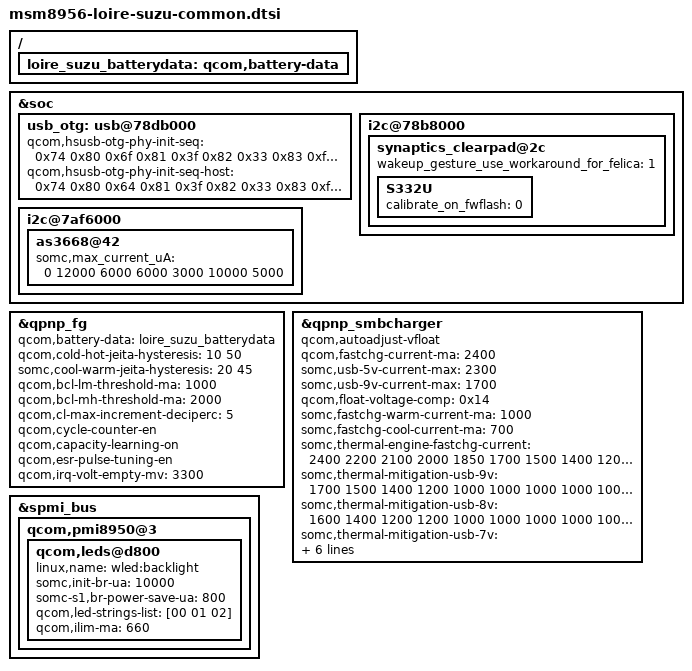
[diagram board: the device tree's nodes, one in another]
/* arch/arm64/boot/dts/qcom/msm8956-loire-suzu-common.dtsi
 *
 * This program is free software; you can redistribute it and/or modify
 * it under the terms of the GNU General Public License version 2 and
 * only version 2 as published by the Free Software Foundation.
 *
 * This program is distributed in the hope that it will be useful,
 * but WITHOUT ANY WARRANTY; without even the implied warranty of
 * MERCHANTABILITY or FITNESS FOR A PARTICULAR PURPOSE.  See the
 * GNU General Public License for more details.
 */
/*
 * Copyright (C) 2015 Sony Mobile Communications Inc.
 *
 * This program is free software; you can redistribute it and/or modify
 * it under the terms of the GNU General Public License version 2, as
 * published by the Free Software Foundation.
 */

&soc {
	usb_otg: usb@78db000 {
		qcom,hsusb-otg-phy-init-seq =
			<0x74 0x80 0x6f 0x81 0x3f 0x82 0x33 0x83 0xffffffff>;
		qcom,hsusb-otg-phy-init-seq-host =
			<0x74 0x80 0x64 0x81 0x3f 0x82 0x33 0x83 0xffffffff>;
	};

	/* I2C : BLSP4 */
	i2c@78b8000 { /* BLSP1 QUP3 */
		synaptics_clearpad@2c {
			wakeup_gesture_use_workaround_for_felica = <1>;
			/* chip settings */
			S332U {
				calibrate_on_fwflash = <0>;
			};
		};
	};
	/* I2C : BLSP6 */
	i2c@7af6000 { /* BLSP2 QUP1 */
		as3668@42 {
			somc,max_current_uA = <0 12000 6000 6000 3000 10000 5000>;
		};
	};
};

/{
	loire_suzu_batterydata: qcom,battery-data {
		#include "batterydata-loire-suzu-send.dtsi"
		#include "batterydata-loire-suzu-atl.dtsi"
	};
};

&qpnp_fg {
	qcom,battery-data = <&loire_suzu_batterydata>;
	qcom,cold-hot-jeita-hysteresis = <10 50>;
	somc,cool-warm-jeita-hysteresis = <20 45>;
	qcom,bcl-lm-threshold-ma = <1000>;
	qcom,bcl-mh-threshold-ma = <2000>;
	qcom,cl-max-increment-deciperc = <5>;
	qcom,cycle-counter-en;
	qcom,capacity-learning-on;
	qcom,esr-pulse-tuning-en;
	qcom,irq-volt-empty-mv = <3300>;
};

&qpnp_smbcharger {
	qcom,autoadjust-vfloat;
	qcom,fastchg-current-ma = <2400>;
	somc,usb-5v-current-max = <2300>;
	somc,usb-9v-current-max = <1700>;
	qcom,float-voltage-comp = <0x14>;
	somc,fastchg-warm-current-ma = <1000>;
	somc,fastchg-cool-current-ma = <700>;
	somc,thermal-engine-fastchg-current = <2400 2200 2100 2000 1850 1700 1500 1400 1200 1100 1100 1000 1000 700 450>;
	somc,thermal-mitigation-usb-9v = <1700 1500 1400 1200 1000 1000 1000 1000 1000 900 700 500 450 300 300>;
	somc,thermal-mitigation-usb-8v = <1600 1400 1200 1200 1000 1000 1000 1000 1000 900 700 500 450 300 300>;
	somc,thermal-mitigation-usb-7v = <1500 1500 1400 1200 1000 1000 1000 1000 1000 900 700 500 450 300 300>;
	somc,thermal-mitigation-usb-6v = <1400 1400 1200 1200 1200 1000 1000 1000 1000 900 700 500 450 300 300>;
	somc,thermal-mitigation-usb-5v = <2300 2200 2100 2000 1800 1600 1400 1200 1200 1100 900 700 500 450 300>;
	somc,limit-usb-5v-level = <15>;
};

&spmi_bus {
	qcom,pmi8950@3 {
		qcom,leds@d800 {
			linux,name = "wled:backlight";
			somc,init-br-ua = <10000>;
			somc-s1,br-power-save-ua = <800>;
			qcom,led-strings-list = [00 01 02];
			qcom,ilim-ma = <660>;
		};
	};
};
